AUTOSAR XML (schema 4-2-2)
package /Components
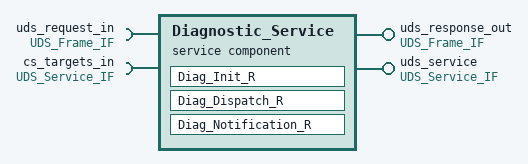
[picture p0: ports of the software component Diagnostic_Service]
  service sw component type Diagnostic_Service
    provide port uds_response_out: provided-interface=UDS_Frame_IF
    provide port uds_service: provided-interface=UDS_Service_IF
    require port uds_request_in: required-interface=UDS_Frame_IF
    require port cs_targets_in: required-interface=UDS_Service_IF
    behavior Diagnostic_Service_InternalBehavior
      asynchronous server call returns event CS_Returns: start-on-event=Diag_Dispatch_R, event-source=ResultPoint
      init event Diag_Init: start-on-event=Diag_Init_R
      operation invoked event UDS_Request_Invoked: start-on-event=Diag_Dispatch_R, operation=uds_service.read_did
      runnable Diag_Init_R
        parameter access PA_Init_DidMap: accessed-parameter=uds_request_in.uds_request_frame
      runnable Diag_Dispatch_R
        data-send-points:
          access VA_Send_UdsResp: accessed-variable=uds_response_out.uds_response_frame
        async call ASCP_RoutineControl: operation=cs_targets_in.routine_control, timeout=200
        sync call SCP_ReadDid: operation=cs_targets_in.read_did, timeout=100
        sync call SCP_WriteDid: operation=cs_targets_in.write_did, timeout=150
      runnable Diag_Notification_R
        data-receive-point-by-values:
          access VA_Recv_UdsReq: accessed-variable=uds_request_in.uds_request_frame
